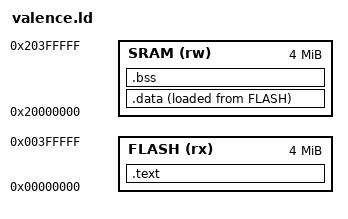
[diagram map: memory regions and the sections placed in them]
/* generated by neuraltransistor -- link map for mps2-an385 (cortex-m3)
 *
 * This is the EMULATOR's memory map, not nRF52840's. It exists so the image
 * boots under qemu-system-arm; fitting a real part is checked separately, by
 * comparing the linked section sizes against that part's datasheet capacity.
 */
MEMORY {
  FLASH (rx) : ORIGIN = 0x00000000, LENGTH = 4194304
  SRAM  (rw) : ORIGIN = 0x20000000, LENGTH = 4194304
}
ENTRY(reset_handler)
SECTIONS {
  .text : {
    KEEP(*(.vectors))
    *(.text*)
    *(.rodata*)
    . = ALIGN(4);
  } > FLASH
  _sidata = LOADADDR(.data);
  .data : {
    . = ALIGN(4);
    _sdata = .;
    *(.data*)
    . = ALIGN(4);
    _edata = .;
  } > SRAM AT > FLASH
  .bss (NOLOAD) : {
    . = ALIGN(4);
    _sbss = .;
    *(.bss*)
    *(COMMON)
    . = ALIGN(4);
    _ebss = .;
  } > SRAM
  _stack_top = ORIGIN(SRAM) + LENGTH(SRAM);
}
